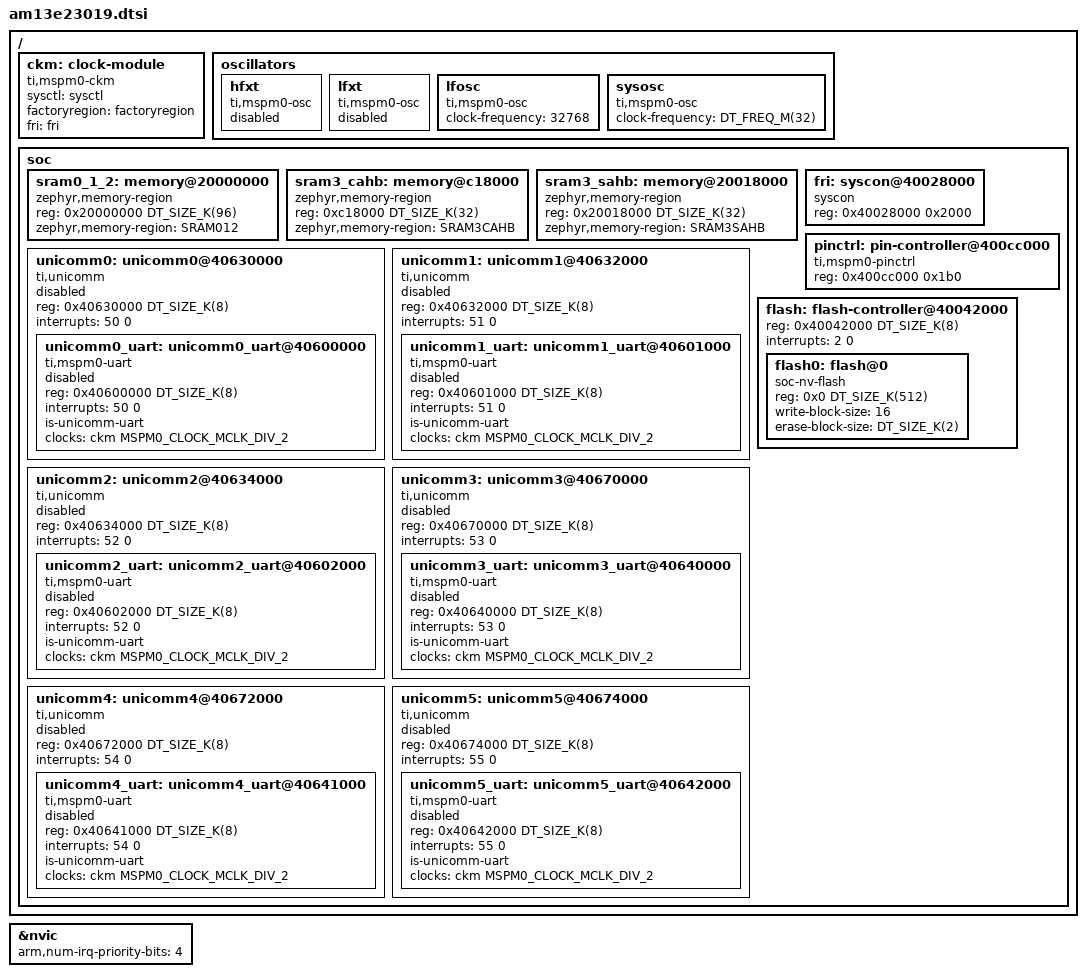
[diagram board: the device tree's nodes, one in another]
/*
 * Copyright (c) 2026 Texas Instruments Incorporated
 *
 * SPDX-License-Identifier: Apache-2.0
 */

#include "am13e.dtsi"
#include <zephyr/dt-bindings/clock/mspm0_clock.h>

/ {
	#address-cells = <1>;
	#size-cells = <1>;

	ckm: clock-module {
		compatible = "ti,mspm0-ckm";
		#clock-cells = <1>;
		sysctl = <&sysctl>;
		factoryregion = <&factoryregion>;
		fri = <&fri>;
	};

	oscillators: oscillators {
		hfxt: hfxt {
			#clock-cells = <0>;
			compatible = "ti,mspm0-osc";
			status = "disabled";
		};

		lfxt: lfxt {
			#clock-cells = <0>;
			compatible = "ti,mspm0-osc";
			status = "disabled";
		};

		lfosc: lfosc {
			#clock-cells = <0>;
			compatible = "ti,mspm0-osc";
			clock-frequency = <32768>;
		};

		sysosc: sysosc {
			#clock-cells = <0>;
			compatible = "ti,mspm0-osc";
			clock-frequency = <DT_FREQ_M(32)>;
		};
	};

	soc {
		sram0_1_2: memory@20000000 {
			compatible = "zephyr,memory-region";
			reg = <0x20000000 DT_SIZE_K(96)>;
			zephyr,memory-region = "SRAM012";
		};

		sram3_cahb: memory@c18000 {
			compatible = "zephyr,memory-region";
			reg = <0xc18000 DT_SIZE_K(32)>;
			zephyr,memory-region = "SRAM3CAHB";
		};

		sram3_sahb: memory@20018000 {
			compatible = "zephyr,memory-region";
			reg = <0x20018000 DT_SIZE_K(32)>;
			zephyr,memory-region = "SRAM3SAHB";
		};

		fri: syscon@40028000 {
			compatible = "syscon";
			reg = <0x40028000 0x2000>;
		};

		pinctrl: pin-controller@400cc000 {
			compatible = "ti,mspm0-pinctrl";
			reg = <0x400cc000 0x1b0>;
		};

		unicomm0: unicomm0@40630000 {
			reg = <0x40630000 DT_SIZE_K(8)>;
			compatible = "ti,unicomm";
			interrupts = <50 0>;
			#address-cells = <1>;
			#size-cells = <1>;
			status = "disabled";

			unicomm0_uart: unicomm0_uart@40600000 {
				reg = <0x40600000 DT_SIZE_K(8)>;
				interrupts = <50 0>;
				#address-cells = <1>;
				#size-cells = <1>;
				compatible = "ti,mspm0-uart";
				is-unicomm-uart;
				clocks = <&ckm MSPM0_CLOCK_MCLK_DIV_2>;
				status = "disabled";
			};
		};

		unicomm1: unicomm1@40632000 {
			reg = <0x40632000 DT_SIZE_K(8)>;
			compatible = "ti,unicomm";
			interrupts = <51 0>;
			#address-cells = <1>;
			#size-cells = <1>;
			status = "disabled";

			unicomm1_uart: unicomm1_uart@40601000 {
				reg = <0x40601000 DT_SIZE_K(8)>;
				interrupts = <51 0>;
				#address-cells = <1>;
				#size-cells = <1>;
				compatible = "ti,mspm0-uart";
				is-unicomm-uart;
				clocks = <&ckm MSPM0_CLOCK_MCLK_DIV_2>;
				status = "disabled";
			};
		};

		unicomm2: unicomm2@40634000 {
			reg = <0x40634000 DT_SIZE_K(8)>;
			compatible = "ti,unicomm";
			interrupts = <52 0>;
			#address-cells = <1>;
			#size-cells = <1>;
			status = "disabled";

			unicomm2_uart: unicomm2_uart@40602000 {
				reg = <0x40602000 DT_SIZE_K(8)>;
				interrupts = <52 0>;
				#address-cells = <1>;
				#size-cells = <1>;
				compatible = "ti,mspm0-uart";
				is-unicomm-uart;
				clocks = <&ckm MSPM0_CLOCK_MCLK_DIV_2>;
				status = "disabled";
			};
		};

		unicomm3: unicomm3@40670000 {
			reg = <0x40670000 DT_SIZE_K(8)>;
			compatible = "ti,unicomm";
			interrupts = <53 0>;
			#address-cells = <1>;
			#size-cells = <1>;
			status = "disabled";

			unicomm3_uart: unicomm3_uart@40640000 {
				reg = <0x40640000 DT_SIZE_K(8)>;
				interrupts = <53 0>;
				#address-cells = <1>;
				#size-cells = <1>;
				compatible = "ti,mspm0-uart";
				is-unicomm-uart;
				clocks = <&ckm MSPM0_CLOCK_MCLK_DIV_2>;
				status = "disabled";
			};
		};

		unicomm4: unicomm4@40672000 {
			reg = <0x40672000 DT_SIZE_K(8)>;
			compatible = "ti,unicomm";
			interrupts = <54 0>;
			#address-cells = <1>;
			#size-cells = <1>;
			status = "disabled";

			unicomm4_uart: unicomm4_uart@40641000 {
				reg = <0x40641000 DT_SIZE_K(8)>;
				interrupts = <54 0>;
				#address-cells = <1>;
				#size-cells = <1>;
				compatible = "ti,mspm0-uart";
				is-unicomm-uart;
				clocks = <&ckm MSPM0_CLOCK_MCLK_DIV_2>;
				status = "disabled";
			};
		};

		unicomm5: unicomm5@40674000 {
			reg = <0x40674000 DT_SIZE_K(8)>;
			compatible = "ti,unicomm";
			interrupts = <55 0>;
			#address-cells = <1>;
			#size-cells = <1>;
			status = "disabled";

			unicomm5_uart: unicomm5_uart@40642000 {
				reg = <0x40642000 DT_SIZE_K(8)>;
				interrupts = <55 0>;
				#address-cells = <1>;
				#size-cells = <1>;
				compatible = "ti,mspm0-uart";
				is-unicomm-uart;
				clocks = <&ckm MSPM0_CLOCK_MCLK_DIV_2>;
				status = "disabled";
			};
		};

		flash: flash-controller@40042000 {
			reg = <0x40042000 DT_SIZE_K(8)>;
			ranges;
			interrupts = <2 0>;

			#address-cells = <1>;
			#size-cells = <1>;

			flash0: flash@0 {
				compatible = "soc-nv-flash";
				reg = <0x0 DT_SIZE_K(512)>;
				ranges = <0x0 0x0 DT_SIZE_K(512)>;

				write-block-size = <16>;
				erase-block-size = <DT_SIZE_K(2)>;

				#address-cells = <1>;
				#size-cells = <1>;
			};
		};
	};
};

&nvic {
	arm,num-irq-priority-bits = <4>;
};
